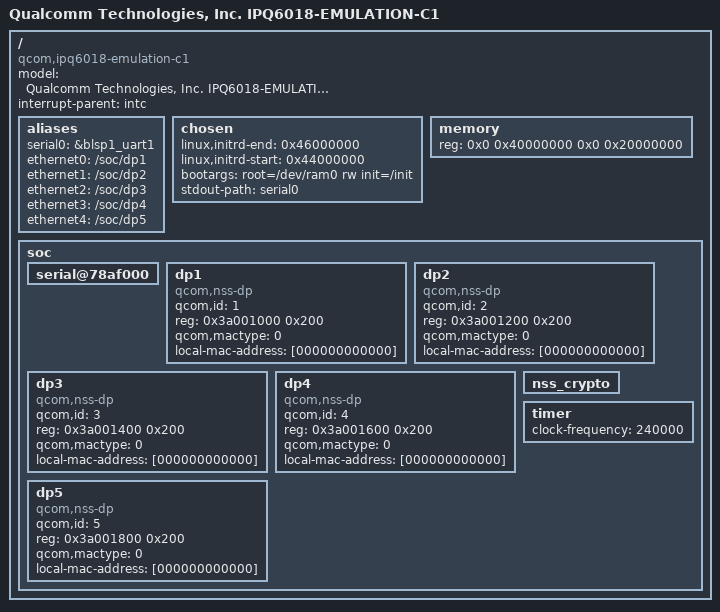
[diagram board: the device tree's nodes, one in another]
/dts-v1/;
/* Copyright (c) 2018, The Linux Foundation. All rights reserved.
 *
 * Permission to use, copy, modify, and/or distribute this software for any
 * purpose with or without fee is hereby granted, provided that the above
 * copyright notice and this permission notice appear in all copies.
 *
 * THE SOFTWARE IS PROVIDED "AS IS" AND THE AUTHOR DISCLAIMS ALL WARRANTIES
 * WITH REGARD TO THIS SOFTWARE INCLUDING ALL IMPLIED WARRANTIES OF
 * MERCHANTABILITY AND FITNESS. IN NO EVENT SHALL THE AUTHOR BE LIABLE FOR
 * ANY SPECIAL, DIRECT, INDIRECT, OR CONSEQUENTIAL DAMAGES OR ANY DAMAGES
 * WHATSOEVER RESULTING FROM LOSS OF USE, DATA OR PROFITS, WHETHER IN AN
 * ACTION OF CONTRACT, NEGLIGENCE OR OTHER TORTIOUS ACTION, ARISING OUT OF
 * OR IN CONNECTION WITH THE USE OR PERFORMANCE OF THIS SOFTWARE.
 */
#include "qcom-ipq6018.dtsi"

/ {
	#address-cells = <0x2>;
	#size-cells = <0x2>;
	model = "Qualcomm Technologies, Inc. IPQ6018-EMULATION-C1";
	compatible = "qcom,ipq6018-emulation-c1", "qcom,ipq6018";
	interrupt-parent = <&intc>;

	aliases {
		serial0 = &blsp1_uart1;
		/*
		 * Aliases as required by u-boot
		 * to patch MAC addresses
		 */
		ethernet0 = "/soc/dp1";
		ethernet1 = "/soc/dp2";
		ethernet2 = "/soc/dp3";
		ethernet3 = "/soc/dp4";
		ethernet4 = "/soc/dp5";
	};

	chosen {
		linux,initrd-end = <0x46000000>;
		linux,initrd-start = <0x44000000>;
		bootargs = "root=/dev/ram0 rw init=/init";
		stdout-path = "serial0";
	};

	memory {
		device_type = "memory";
		reg = <0x0 0x40000000 0x0 0x20000000>;
	};

	soc {
		serial@78af000 {
			status = "ok";
		};

		dp1 {
			device_type = "network";
			compatible = "qcom,nss-dp";
			qcom,id = <1>;
			reg = <0x3a001000 0x200>;
			qcom,mactype = <0>;
			local-mac-address = [000000000000];
		};

		dp2 {
			device_type = "network";
			compatible = "qcom,nss-dp";
			qcom,id = <2>;
			reg = <0x3a001200 0x200>;
			qcom,mactype = <0>;
			local-mac-address = [000000000000];
		};

		dp3 {
			device_type = "network";
			compatible = "qcom,nss-dp";
			qcom,id = <3>;
			reg = <0x3a001400 0x200>;
			qcom,mactype = <0>;
			local-mac-address = [000000000000];
		};

		dp4 {
			device_type = "network";
			compatible = "qcom,nss-dp";
			qcom,id = <4>;
			reg = <0x3a001600 0x200>;
			qcom,mactype = <0>;
			local-mac-address = [000000000000];
		};

		dp5 {
			device_type = "network";
			compatible = "qcom,nss-dp";
			qcom,id = <5>;
			reg = <0x3a001800 0x200>;
			qcom,mactype = <0>;
			local-mac-address = [000000000000];
		};

		nss_crypto {
			status = "ok";
		};

		timer {
			clock-frequency = <240000>;
		};
	};
};
